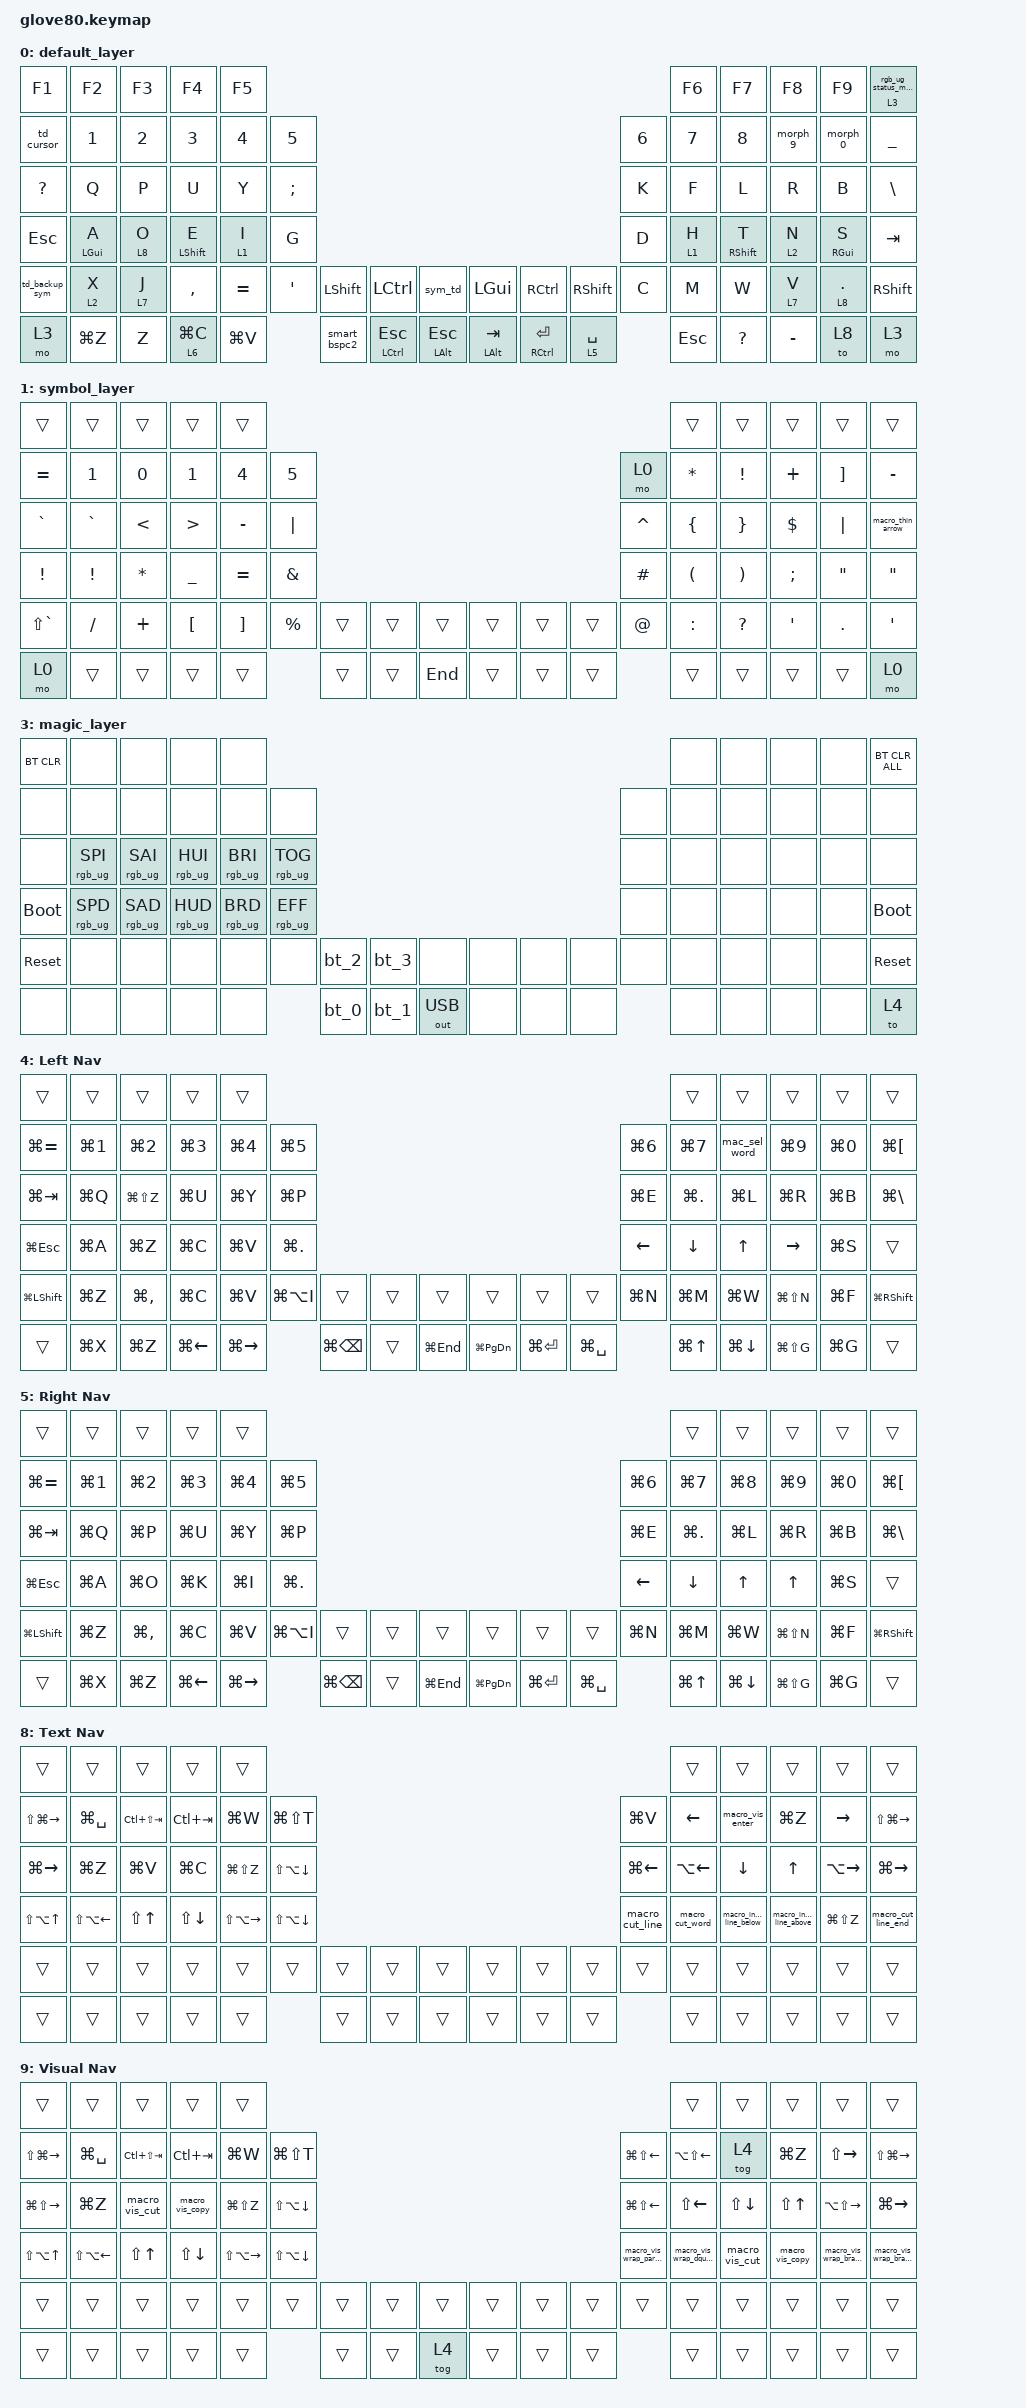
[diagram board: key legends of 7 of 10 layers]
/*
 * Copyright (c) 2020 The ZMK Contributors
 *
 * SPDX-License-Identifier: MIT
 */

#include <dt-bindings/zmk/mouse.h>
#include <behaviors.dtsi>
#include <dt-bindings/zmk/bt.h>
#include <dt-bindings/zmk/keys.h>
#include <dt-bindings/zmk/outputs.h>
#include <dt-bindings/zmk/rgb.h>

// layers

#define DEFAULT 0
#define LOWER 1
#define MAGIC 2
#define FACTORY_TEST 3
#define SYMBOL 4
#define NAV 5
#define LAUNCHER 6
#define CMD_NUM_LAY_2 7
#define TEXT_NAV 8
#define VISUAL_NAV 9
#define KEYS_L 0 1 2 3 4 10 11 12 13 14 15 22 23 24 25 26 27 34 35 36 37 38 39 46 47 48 49 50 51 52 53 54 69 70 71
#define KEYS_R 5 6 7 8 9 16 17 18 19 20 21 28 29 30 31 32 33 40 41 42 43 44 45 55 56 57 58 59 60 61 62 63 72 73 74

/ {
    behaviors {
        // For the "layer" key, it'd nice to be able to use it as either a shift or a toggle.
        // Configure it as a tap dance, so the first tap (or hold) is a &mo and the second tap is a &to

        layer_td: tap_dance_0 {
            compatible = "zmk,behavior-tap-dance";
            label = "LAYER_TAP_DANCE";
            #binding-cells = <0>;
            tapping-term-ms = <200>;
            bindings = <&mo 2>, <&to 2>;
        };

        // Custom Symbol Toggle

        sym_td: symbol_tap_dance {
            compatible = "zmk,behavior-tap-dance";
            label = "SYMBOL_TAP_DANCE";
            #binding-cells = <0>;
            tapping-term-ms = <175>;
            bindings = <&mo 1>, <&to 1>;
        };

        // Custom Nav Toggle

        nav_td: nav_tap_dance {
            compatible = "zmk,behavior-tap-dance";
            label = "NAV_TAP_DANCE";
            #binding-cells = <0>;
            tapping-term-ms = <175>;
            bindings = <&mo 5>, <&to 5>;
        };

        magic: magic_hold_tap {
            compatible = "zmk,behavior-hold-tap";
            label = "MAGIC_HOLD_TAP";
            #binding-cells = <2>;
            flavor = "tap-preferred";
            tapping-term-ms = <200>;
            bindings = <&mo>, <&rgb_ug_status_macro>;
        };

        // Custom Enter/Nav Layer behavior

        ent_nav: enter_nav_layer {
            compatible = "zmk,behavior-hold-tap";
            label = "ENTER_NAV_LAYER";
            #binding-cells = <2>;
            flavor = "tap-preferred";
            tapping-term-ms = <175>;
            quick-tap-ms = <0>;
            retro-tap;
            bindings = <&mo>, <&kp>;
        };

        // Custom Less Than/Launcher Layer behavior

        less_lnch: less_than_launcher {
            compatible = "zmk,behavior-hold-tap";
            label = "LESS_THAN_LAUNCHER";
            #binding-cells = <2>;
            flavor = "tap-preferred";
            tapping-term-ms = <220>;
            quick-tap-ms = <200>;
            require-prior-idle-ms = <125>;
            retro-tap;
            bindings = <&mo>, <&kp>;
        };

        #include "macros.dtsi"

        /* Enter key: Tap for Enter, Hold for Command/GUI */

        enter_cmd: enter_command {
            compatible = "zmk,behavior-hold-tap";
            label = "ENTER_COMMAND";
            #binding-cells = <2>;
            tapping-term-ms = <200>;
            quick-tap-ms = <175>;
            flavor = "balanced";
            bindings = <&kp>, <&kp>;
        };

        /* Left thumb backspace that becomes Shift when held */

        bs_shift: backspace_shift {
            compatible = "zmk,behavior-hold-tap";
            label = "BACKSPACE_SHIFT";
            #binding-cells = <2>;
            tapping-term-ms = <220>;
            quick-tap-ms = <175>;
            require-prior-idle-ms = <160>;
            flavor = "tap-preferred";
            retro-tap;
            bindings = <&kp>, <&kp>;
        };

        /* Right thumb space that becomes Shift when held */

        sp_shift: space_shift {
            compatible = "zmk,behavior-hold-tap";
            label = "SPACE_SHIFT";
            #binding-cells = <2>;
            tapping-term-ms = <220>;
            quick-tap-ms = <0>;
            require-prior-idle-ms = <140>;
            flavor = "tap-preferred";
            retro-tap;
            bindings = <&kp>, <&kp>;
        };

        sp_nav: space_nav {
            compatible = "zmk,behavior-hold-tap";
            label = "SPACE_NAV";
            #binding-cells = <2>;
            tapping-term-ms = <220>;
            quick-tap-ms = <0>;
            require-prior-idle-ms = <140>;
            flavor = "tap-preferred";
            retro-tap;
            bindings = <&mo>, <&kp>;
        };

        /* Smart Toggle for Sym Layer: Tap=Sticky, DoubleTap=Toggle */
        /* Hold-Tap for Sym Layer: Hold=Momentary(1), Tap=Sticky(1) */
        /* Smart Toggle for Sym Layer: Tap=Sticky(via ht), DoubleTap=Lock(tog) */
        /* Select Word: Normal=right, Shift=left */
        /* Smart Backspace: Normal=BSPC/Shift (Hold-Tap), Shift=DelWord (Option+BSPC) */

        bs_nav: backspace_nav {
            compatible = "zmk,behavior-hold-tap";
            label = "BACKSPACE_NAV";
            #binding-cells = <2>;
            tapping-term-ms = <220>;
            quick-tap-ms = <175>;
            require-prior-idle-ms = <160>;
            flavor = "tap-preferred";
            retro-tap;
            bindings = <&mo>, <&kp>;
        };

        smart_bspc: smart_backspace {
            compatible = "zmk,behavior-mod-morph";
            label = "SMART_BACKSPACE";
            #binding-cells = <0>;
            bindings = <&bs_shift LSHFT BSPC>, <&kp LA(BSPC)>;

            mods = <(MOD_LSFT|MOD_RSFT)>;
        };

        smart_bspc2: smart_backspace_2 {
            compatible = "zmk,behavior-mod-morph";
            label = "SMART_BACKSPACE_2";
            #binding-cells = <0>;
            bindings = <&bs_nav 4 BSPC>, <&kp LA(BSPC)>;

            mods = <(MOD_LSFT|MOD_RSFT)>;
        };

        select_word: select_word {
            compatible = "zmk,behavior-mod-morph";
            label = "SELECT_WORD";
            #binding-cells = <0>;
            bindings = <&Mac_Select_Word_Right>, <&Mac_Select_Word_Left>;

            mods = <(MOD_LSFT|MOD_RSFT)>;
        };

        /* Select Line: Normal=right, Shift=left */

        select_line: select_line {
            compatible = "zmk,behavior-mod-morph";
            label = "SELECT_LINE";
            #binding-cells = <0>;
            bindings = <&Mac_Select_Line_Right>, <&Mac_Select_Line_Left>;

            mods = <(MOD_LSFT|MOD_RSFT)>;
        };

        /* Extend Word: Normal=right, Shift=left */

        extend_word: extend_word {
            compatible = "zmk,behavior-mod-morph";
            label = "EXTEND_WORD";
            #binding-cells = <0>;
            bindings = <&Mac_Extend_Word_Right>, <&Mac_Extend_Word_Left>;

            mods = <(MOD_LSFT|MOD_RSFT)>;
        };

        /* Extend Line: Normal=down, Shift=up */

        extend_line: extend_line {
            compatible = "zmk,behavior-mod-morph";
            label = "EXTEND_LINE";
            #binding-cells = <0>;
            bindings = <&Mac_Extend_Line_Down>, <&Mac_Extend_Line_Up>;

            mods = <(MOD_LSFT|MOD_RSFT)>;
        };

        /* Hold-Tap for Nav Layer: Hold=Momentary(4), Tap=Sticky(4) */
        /* Note: Double-tap to toggle is removed to fix build compatibility constraints */

        lt_nav_enter: layer_tap_nav_enter {
            compatible = "zmk,behavior-hold-tap";
            label = "LAYER_TAP_NAV_ENTER";
            #binding-cells = <2>;
            tapping-term-ms = <175>;
            quick-tap-ms = <0>;
            flavor = "tap-preferred";
            retro-tap;
            bindings = <&mo>, <&kp>;
        };

        lt_launcher: layer_tap_launcher {
            compatible = "zmk,behavior-hold-tap";
            label = "LAYER_TAP_LAUNCHER";
            #binding-cells = <2>;
            tapping-term-ms = <220>;
            quick-tap-ms = <0>;
            require-prior-idle-ms = <180>;
            flavor = "tap-preferred";
            retro-tap;
            bindings = <&mo>, <&kp>;
        };

        mt_ctrl_enter: mod_tap_ctrl_enter {
            compatible = "zmk,behavior-hold-tap";
            label = "MOD_TAP_CTRL_ENTER";
            #binding-cells = <2>;
            tapping-term-ms = <175>;
            quick-tap-ms = <0>;
            flavor = "tap-preferred";
            retro-tap;
            bindings = <&kp>, <&kp>;
        };

        mt_ctrl_esc: mod_tap_ctrl_esc {
            compatible = "zmk,behavior-hold-tap";
            label = "MOD_TAP_CTRL_ESC";
            #binding-cells = <2>;
            tapping-term-ms = <220>;
            quick-tap-ms = <0>;
            require-prior-idle-ms = <140>;
            flavor = "tap-preferred";
            retro-tap;
            bindings = <&kp>, <&kp>;
        };

        mt_opt_esc: mod_tap_opt_esc {
            compatible = "zmk,behavior-hold-tap";
            label = "MOD_TAP_OPT_ESC";
            #binding-cells = <2>;
            tapping-term-ms = <200>;
            quick-tap-ms = <0>;
            require-prior-idle-ms = <140>;
            flavor = "tap-preferred";
            retro-tap;
            bindings = <&kp>, <&kp>;
        };

        mt_opt_tab: mod_tap_opt_tab {
            compatible = "zmk,behavior-hold-tap";
            label = "MOD_TAP_OPT_TAB";
            #binding-cells = <2>;
            tapping-term-ms = <200>;
            quick-tap-ms = <0>;
            require-prior-idle-ms = <140>;
            flavor = "tap-preferred";
            retro-tap;
            bindings = <&kp>, <&kp>;
        };

        hrm_left_index: homerow_mod_left_sym {
            compatible = "zmk,behavior-hold-tap";
            label = "HOMEROW_MOD_LEFT_SYM";
            #binding-cells = <2>;
            tapping-term-ms = <295>;
            quick-tap-ms = <175>;
            require-prior-idle-ms = <200>;
            flavor = "tap-preferred";
            retro-tap;
            bindings = <&mo>, <&kp>;

            hold-trigger-key-positions = <KEYS_R>;
            hold-trigger-on-release;
        };

        hrm_left_ring: homerow_mod_left_ring_sym {
            compatible = "zmk,behavior-hold-tap";
            label = "HOMEROW_MOD_LEFT_RING_SYM";
            #binding-cells = <2>;
            tapping-term-ms = <320>;
            quick-tap-ms = <210>;
            require-prior-idle-ms = <200>;
            flavor = "tap-preferred";
            retro-tap;
            bindings = <&mo>, <&kp>;

            hold-trigger-key-positions = <KEYS_R>;
            hold-trigger-on-release;
        };

        hrm_right_index: homerow_mod_right_sym {
            compatible = "zmk,behavior-hold-tap";
            label = "HOMEROW_MOD_RIGHT_SYM";
            #binding-cells = <2>;
            tapping-term-ms = <270>;
            quick-tap-ms = <160>;
            require-prior-idle-ms = <200>;
            flavor = "tap-preferred";
            retro-tap;
            bindings = <&mo>, <&kp>;

            hold-trigger-key-positions = <KEYS_L>;
            hold-trigger-on-release;
        };

        hrm_right_ring: homerow_mod_right_ring_sym {
            compatible = "zmk,behavior-hold-tap";
            label = "HOMEROW_MOD_RIGHT_RING_SYM";
            #binding-cells = <2>;
            tapping-term-ms = <265>;
            quick-tap-ms = <160>;
            require-prior-idle-ms = <200>;
            flavor = "tap-preferred";
            retro-tap;
            bindings = <&mo>, <&kp>;

            hold-trigger-key-positions = <KEYS_L>;
            hold-trigger-on-release;
        };

        hrm_left_ring_bottom: homerow_mod_left_ring_bottom_layer {
            compatible = "zmk,behavior-hold-tap";
            label = "HOMEROW_MOD_LEFT_RING_BOTTOM_LAYER";
            #binding-cells = <2>;
            tapping-term-ms = <290>;
            quick-tap-ms = <175>;
            require-prior-idle-ms = <200>;
            flavor = "tap-preferred";
            retro-tap;
            bindings = <&mo>, <&kp>;

            hold-trigger-key-positions = <KEYS_R>;
            hold-trigger-on-release;
        };

        hrm_right_ring_bottom: homerow_mod_right_ring_bottom_layer {
            compatible = "zmk,behavior-hold-tap";
            label = "HOMEROW_MOD_RIGHT_RING_BOTTOM_LAYER";
            #binding-cells = <2>;
            tapping-term-ms = <265>;
            quick-tap-ms = <160>;
            require-prior-idle-ms = <200>;
            flavor = "tap-preferred";
            retro-tap;
            bindings = <&mo>, <&kp>;

            hold-trigger-key-positions = <KEYS_L>;
            hold-trigger-on-release;
        };

        hrm_left_middle: homerow_mod_left_shift {
            compatible = "zmk,behavior-hold-tap";
            label = "HOMEROW_MOD_LEFT_SHIFT";
            #binding-cells = <2>;
            tapping-term-ms = <315>;
            quick-tap-ms = <160>;
            require-prior-idle-ms = <200>;
            flavor = "tap-preferred";
            retro-tap;
            bindings = <&kp>, <&kp>;

            hold-trigger-key-positions = <KEYS_R>;
            hold-trigger-on-release;
        };

        hrm_right_middle: homerow_mod_right_shift {
            compatible = "zmk,behavior-hold-tap";
            label = "HOMEROW_MOD_RIGHT_SHIFT";
            #binding-cells = <2>;
            tapping-term-ms = <280>;
            quick-tap-ms = <160>;
            require-prior-idle-ms = <200>;
            flavor = "tap-preferred";
            retro-tap;
            bindings = <&kp>, <&kp>;

            hold-trigger-key-positions = <KEYS_L>;
            hold-trigger-on-release;
        };

        hrm_left_pinky: homerow_mod_left_cmd {
            compatible = "zmk,behavior-hold-tap";
            label = "HOMEROW_MOD_LEFT_CMD";
            #binding-cells = <2>;
            tapping-term-ms = <365>;
            quick-tap-ms = <175>;
            require-prior-idle-ms = <200>;
            flavor = "tap-preferred";
            retro-tap;
            bindings = <&kp>, <&kp>;

            hold-trigger-key-positions = <KEYS_R>;
            hold-trigger-on-release;
        };

        hrm_left_pinky_bottom: homerow_mod_left_pinky_bottom_layer {
            compatible = "zmk,behavior-hold-tap";
            label = "HOMEROW_MOD_LEFT_PINKY_BOTTOM_LAYER";
            #binding-cells = <2>;
            tapping-term-ms = <365>;
            quick-tap-ms = <175>;
            require-prior-idle-ms = <200>;
            flavor = "tap-preferred";
            retro-tap;
            bindings = <&mo>, <&kp>;

            hold-trigger-key-positions = <KEYS_R>;
            hold-trigger-on-release;
        };

        hrm_right_pinky: homerow_mod_right_cmd {
            compatible = "zmk,behavior-hold-tap";
            label = "HOMEROW_MOD_RIGHT_CMD";
            #binding-cells = <2>;
            tapping-term-ms = <300>;
            quick-tap-ms = <160>;
            require-prior-idle-ms = <200>;
            flavor = "tap-preferred";
            retro-tap;
            bindings = <&kp>, <&kp>;

            hold-trigger-key-positions = <KEYS_L>;
            hold-trigger-on-release;
        };

        hrm_right_pinky_bottom: homerow_mod_right_pinky_bottom_layer {
            compatible = "zmk,behavior-hold-tap";
            label = "HOMEROW_MOD_RIGHT_PINKY_BOTTOM_LAYER";
            #binding-cells = <2>;
            tapping-term-ms = <300>;
            quick-tap-ms = <160>;
            require-prior-idle-ms = <200>;
            flavor = "tap-preferred";
            retro-tap;
            bindings = <&mo>, <&kp>;

            hold-trigger-key-positions = <KEYS_L>;
            hold-trigger-on-release;
        };

        /* Smart Toggle for Nav Layer (Layer 4): Tap=Sticky, Hold=Momentary */
        /* Replaced Tap-Dance with Hold-Tap for instant speed (Option A) */
        /* Hold-Tap for Cursor Layer: Hold=Momentary(5), Tap=Sticky(5) */
        /* Smart Toggle for Sym Layer: Tap=Sticky, DoubleTap=Lock(tog) */

        td_backup_sym: tap_dance_backup_sym {
            compatible = "zmk,behavior-tap-dance";
            label = "TAP_DANCE_BACKUP_SYM";
            #binding-cells = <0>;
            tapping-term-ms = <175>;
            bindings = <&sl 6>, <&tog 6>;
        };

        /* Smart Toggle for Cursor Layer: Tap=Sticky, DoubleTap=Lock(tog) */

        td_cursor: tap_dance_cursor {
            compatible = "zmk,behavior-tap-dance";
            label = "TAP_DANCE_CURSOR";
            #binding-cells = <0>;
            tapping-term-ms = <175>;
            bindings = <&sl 0>, <&tog 0>;
        };

        fat_arrow: fat_arrow_morph {
            compatible = "zmk,behavior-mod-morph";
            label = "FAT_ARROW_MORPH";
            #binding-cells = <0>;
            bindings = <&kp MINUS>, <&macro_fat_arrow>;

            mods = <(MOD_LSFT|MOD_RSFT)>;
        };

        add_assign: add_assign_morph {
            compatible = "zmk,behavior-mod-morph";
            label = "ADD_ASSIGN_MORPH";
            #binding-cells = <0>;
            bindings = <&kp PLUS>, <&macro_add_assign>;

            mods = <(MOD_LSFT|MOD_RSFT)>;
        };

        not_equal: not_equal_morph {
            compatible = "zmk,behavior-mod-morph";
            label = "NOT_EQUAL_MORPH";
            #binding-cells = <0>;
            bindings = <&kp COLON>, <&macro_not_equal>;

            mods = <(MOD_LSFT|MOD_RSFT)>;
        };

        underscore_arrow: underscore_arrow_morph {
            compatible = "zmk,behavior-mod-morph";
            label = "UNDERSCORE_ARROW_MORPH";
            #binding-cells = <0>;
            bindings = <&kp UNDER>, <&macro_thin_arrow>;

            mods = <(MOD_LSFT|MOD_RSFT)>;
        };

        morph_9: morph_9_lbracket {
            compatible = "zmk,behavior-mod-morph";
            label = "MORPH_9_LBRACKET";
            #binding-cells = <0>;
            bindings = <&kp N9>, <&macro_lbracket>;

            mods = <(MOD_LSFT|MOD_RSFT)>;
        };

        morph_0: morph_0_rbracket {
            compatible = "zmk,behavior-mod-morph";
            label = "MORPH_0_RBRACKET";
            #binding-cells = <0>;
            bindings = <&kp N0>, <&macro_rbracket>;

            mods = <(MOD_LSFT|MOD_RSFT)>;
        };

        lcurly_sq: lcurly_square {
            compatible = "zmk,behavior-mod-morph";
            label = "LCURLY_SQUARE";
            #binding-cells = <0>;
            bindings = <&kp LBRC>, <&macro_lbracket>;

            mods = <(MOD_LSFT|MOD_RSFT)>;
        };

        rcurly_sq: rcurly_square {
            compatible = "zmk,behavior-mod-morph";
            label = "RCURLY_SQUARE";
            #binding-cells = <0>;
            bindings = <&kp RBRC>, <&macro_rbracket>;

            mods = <(MOD_LSFT|MOD_RSFT)>;
        };
    };

    macros {
        rgb_ug_status_macro: rgb_ug_status_macro_0 {
            label = "RGB_UG_STATUS";
            compatible = "zmk,behavior-macro";
            #binding-cells = <0>;
            bindings = <&rgb_ug RGB_STATUS>;
        };

        bt_0: bt_profile_macro_0 {
            label = "BT_0";
            compatible = "zmk,behavior-macro";
            #binding-cells = <0>;
            bindings = <&out OUT_BLE &bt BT_SEL 0>;
        };

        bt_1: bt_profile_macro_1 {
            label = "BT_1";
            compatible = "zmk,behavior-macro";
            #binding-cells = <0>;
            bindings = <&out OUT_BLE &bt BT_SEL 1>;
        };

        bt_2: bt_profile_macro_2 {
            label = "BT_2";
            compatible = "zmk,behavior-macro";
            #binding-cells = <0>;
            bindings = <&out OUT_BLE &bt BT_SEL 2>;
        };

        bt_3: bt_profile_macro_3 {
            label = "BT_3";
            compatible = "zmk,behavior-macro";
            #binding-cells = <0>;
            bindings = <&out OUT_BLE &bt BT_SEL 3>;
        };
    };

    keymap {
        compatible = "zmk,keymap";

        default_layer {
            bindings = <
&kp F1          &kp F2                      &kp F3                     &kp F4                    &kp F5                                                                                                                                                                                &kp F6                &kp F7                           &kp F8                      &kp F9                         &magic 3 0
&td_cursor      &kp N1                      &kp N2                     &kp N3                    &kp N4               &kp N5                                                                                                                                                   &kp N6  &kp N7                &kp N8                           &morph_9                    &morph_0                       &kp UNDERSCORE
&kp QUESTION    &kp Q                       &kp P                      &kp U                     &kp Y                &kp SEMI                                                                                                                                                 &kp K   &kp F                 &kp L                            &kp R                       &kp B                          &kp BSLH
&kp ESCAPE      &hrm_left_pinky LGUI A      &hrm_left_ring 8 O         &hrm_left_middle LSHFT E  &hrm_left_index 1 I  &kp G                                                                                                                                                    &kp D   &hrm_right_index 1 H  &hrm_right_middle RIGHT_SHIFT T  &hrm_right_ring 2 N         &hrm_right_pinky RGUI S        &kp TAB
&td_backup_sym  &hrm_left_pinky_bottom 2 X  &hrm_left_ring_bottom 7 J  &kp COMMA                 &kp EQUAL            &kp SINGLE_QUOTE  &kp LSHFT     &kp LCTRL                  &sym_td                    &kp LGUI              &kp RCTRL                   &kp RSHFT        &kp C   &kp M                 &kp W                            &hrm_right_ring_bottom 7 V  &hrm_right_pinky_bottom 8 DOT  &kp RSHFT
&mo 3           &kp LG(Z)                   &kp Z                      &lt_launcher 6 LG(C)      &kp LG(V)                              &smart_bspc2  &mt_ctrl_esc LCTRL ESCAPE  &mt_opt_esc LALT ESCAPE    &mt_opt_tab LALT TAB  &mt_ctrl_enter RCTRL ENTER  &sp_nav 5 SPACE          &kp ESCAPE            &kp QUESTION                     &kp MINUS                   &to 8                          &mo 3
            >;
        };

        symbol_layer {
            bindings = <
&trans           &trans           &trans         &trans            &trans                                                                                            &trans                &trans                 &trans         &trans             &trans
&kp EQUAL        &kp N1           &kp NUMBER_0   &kp NUMBER_1      &kp N4             &kp N5                                                            &mo 0        &kp STAR              &kp EXCLAMATION        &kp PLUS       &kp RIGHT_BRACKET  &kp MINUS
&kp GRAVE        &kp GRAVE        &kp LESS_THAN  &kp GREATER_THAN  &kp MINUS          &kp PIPE                                                          &kp CARET    &kp LEFT_BRACE        &kp RIGHT_BRACE        &kp DOLLAR     &kp PIPE           &macro_thin_arrow
&kp EXCLAMATION  &kp EXCLAMATION  &kp ASTERISK   &kp UNDERSCORE    &kp EQUAL          &kp AMPERSAND                                                     &kp HASH     &kp LEFT_PARENTHESIS  &kp RIGHT_PARENTHESIS  &kp SEMICOLON  &kp DOUBLE_QUOTES  &kp DOUBLE_QUOTES
&kp LS(GRAVE)    &kp SLASH        &kp PLUS       &kp LEFT_BRACKET  &kp RIGHT_BRACKET  &kp PERCENT    &trans  &trans  &trans     &trans  &trans  &trans  &kp AT_SIGN  &kp COLON             &kp QUESTION           &kp SQT        &kp DOT            &kp SINGLE_QUOTE
&mo 0            &trans           &trans         &trans            &trans                            &trans  &trans  &kp END    &trans  &trans  &trans               &trans                &trans                 &trans         &trans             &mo 0
            >;
        };

        num_layer {
            display-name = "Num";
            bindings = <
&trans  &trans      &trans        &trans        &trans                                                                                            &trans                 &trans                 &trans                 &trans                 &trans
&trans  &trans      &kp SLASH     &kp ASTERISK  &trans        &trans                                                       &trans                 &trans                 &trans                 &trans                 &trans                 &trans
&trans  &kp COMMA   &kp NUMBER_4  &kp NUMBER_5  &kp NUMBER_6  &kp PLUS                                                     &kp LS(LA(LC(LG(K))))  &kp LC(LEFT)           &kp LC(UP)             &kp LC(RIGHT)          &kp LG(LA(LC(LS(B))))  &trans
&trans  &kp N0      &kp N1        &kp N2        &kp N3        &kp EQUAL                                                    &kp LG(LA(LC(LS(D))))  &kp LG(LA(LC(LS(H))))  &kp LG(LA(LC(LS(T))))  &kp LG(LA(LC(LS(N))))  &kp LG(LA(LC(LS(S))))  &trans
&trans  &kp PERIOD  &kp N7        &kp N8        &kp N9        &kp MINUS  &trans  &trans  &trans    &trans  &trans  &trans  &kp LG(NUMBER_0)       &kp LG(MINUS)          &kp LG(PLUS)           &kp D                  &kp PERIOD             &trans
&trans  &trans      &trans        &trans        &trans                   &trans  &trans  &trans    &trans  &trans  &trans                         &kp LG(SPACE)          &trans                 &trans                 &trans                 &trans
            >;
        };

        magic_layer {
            bindings = <
&bt BT_CLR   &none            &none            &none            &none                                                                                       &none  &none  &none  &none  &bt BT_CLR_ALL
&none        &none            &none            &none            &none            &none                                                               &none  &none  &none  &none  &none  &none
&none        &rgb_ug RGB_SPI  &rgb_ug RGB_SAI  &rgb_ug RGB_HUI  &rgb_ug RGB_BRI  &rgb_ug RGB_TOG                                                     &none  &none  &none  &none  &none  &none
&bootloader  &rgb_ug RGB_SPD  &rgb_ug RGB_SAD  &rgb_ug RGB_HUD  &rgb_ug RGB_BRD  &rgb_ug RGB_EFF                                                     &none  &none  &none  &none  &none  &bootloader
&sys_reset   &none            &none            &none            &none            &none            &bt_2  &bt_3  &none           &none  &none  &none  &none  &none  &none  &none  &none  &sys_reset
&none        &none            &none            &none            &none                             &bt_0  &bt_1  &out OUT_USB    &none  &none  &none         &none  &none  &none  &none  &to 4
            >;
        };

        cmd_arw_nav_left_hand {
            display-name = "Left Nav";
            bindings = <
&trans         &trans      &trans         &trans        &trans                                                                                                                          &trans          &trans         &trans           &trans      &trans
&kp LG(EQUAL)  &kp LG(N1)  &kp LG(N2)     &kp LG(N3)    &kp LG(N4)     &kp LG(N5)                                                                                       &kp LG(N6)      &kp LG(N7)      &mac_sel_word  &kp LG(N9)       &kp LG(N0)  &kp LG(LBKT)
&kp LG(TAB)    &kp LG(Q)   &kp LG(LS(Z))  &kp LG(U)     &kp LG(Y)      &kp LG(P)                                                                                        &kp LG(E)       &kp LG(DOT)     &kp LG(L)      &kp LG(R)        &kp LG(B)   &kp LG(BSLH)
&kp LG(ESC)    &kp LG(A)   &kp LG(Z)      &kp LG(C)     &kp LG(V)      &kp LG(DOT)                                                                                      &kp LEFT_ARROW  &kp DOWN_ARROW  &kp UP_ARROW   &kp RIGHT_ARROW  &kp LG(S)   &trans
&kp LG(LSHFT)  &kp LG(Z)   &kp LG(COMMA)  &kp LG(C)     &kp LG(V)      &kp LG(LA(I))  &trans        &trans  &trans         &trans         &trans         &trans         &kp LG(N)       &kp LG(M)       &kp LG(W)      &kp LG(LS(N))    &kp LG(F)   &kp LG(RSHFT)
&trans         &kp LG(X)   &kp LG(Z)      &kp LG(LEFT)  &kp LG(RIGHT)                 &kp LG(BSPC)  &trans  &kp LG(END)    &kp LG(PG_DN)  &kp LG(ENTER)  &kp LG(SPACE)                  &kp LG(UP)      &kp LG(DOWN)   &kp LG(LS(G))    &kp LG(G)   &trans
            >;
        };

        cmd_arw_nav_right_hand {
            display-name = "Right Nav";
            bindings = <
&trans         &trans      &trans         &trans        &trans                                                                                                                      &trans          &trans        &trans         &trans      &trans
&kp LG(EQUAL)  &kp LG(N1)  &kp LG(N2)     &kp LG(N3)    &kp LG(N4)     &kp LG(N5)                                                                                       &kp LG(N6)  &kp LG(N7)      &kp LG(N8)    &kp LG(N9)     &kp LG(N0)  &kp LG(LBKT)
&kp LG(TAB)    &kp LG(Q)   &kp LG(P)      &kp LG(U)     &kp LG(Y)      &kp LG(P)                                                                                        &kp LG(E)   &kp LG(PERIOD)  &kp LG(L)     &kp LG(R)      &kp LG(B)   &kp LG(BSLH)
&kp LG(ESC)    &kp LG(A)   &kp LG(O)      &kp LG(K)     &kp LG(I)      &kp LG(DOT)                                                                                      &kp LEFT    &kp DOWN_ARROW  &kp UP_ARROW  &kp UP_ARROW   &kp LG(S)   &trans
&kp LG(LSHFT)  &kp LG(Z)   &kp LG(COMMA)  &kp LG(C)     &kp LG(V)      &kp LG(LA(I))  &trans        &trans  &trans         &trans         &trans         &trans         &kp LG(N)   &kp LG(M)       &kp LG(W)     &kp LG(LS(N))  &kp LG(F)   &kp LG(RSHFT)
&trans         &kp LG(X)   &kp LG(Z)      &kp LG(LEFT)  &kp LG(RIGHT)                 &kp LG(BSPC)  &trans  &kp LG(END)    &kp LG(PG_DN)  &kp LG(ENTER)  &kp LG(SPACE)              &kp LG(UP)      &kp LG(DOWN)  &kp LG(LS(G))  &kp LG(G)   &trans
            >;
        };

        launcher_layer {
            display-name = "Launcher";
            bindings = <
&trans  &trans                 &trans                 &trans        &trans                                                                                                                 &trans                 &trans                 &trans                 &trans                 &trans
&trans  &kp LG(LA(ESC))        &kp LG(LA(LC(LS(P))))  &kp LC(UP)    &kp LG(LA(LC(LS(Y))))  &trans                                                                   &kp LS(LA(LC(LG(K))))  &kp LC(LEFT)           &kp LC(UP)             &kp LC(RIGHT)          &kp LG(LA(LC(LS(B))))  &trans
&trans  &kp LG(LA(LC(LS(A))))  &kp LG(LA(LC(LS(O))))  &kp LC(LEFT)  &kp LC(RIGHT)          &kp LG(LA(LC(LS(G))))                                                    &kp LG(LA(LC(LS(D))))  &kp LG(LA(LC(LS(H))))  &kp LG(LA(LC(LS(T))))  &kp LG(LA(LC(LS(N))))  &kp LG(LA(LC(LS(S))))  &trans
&trans  &kp LG(LS(Q))          &kp LG(LA(LC(LS(J))))  &trans        &trans                 &trans                                                                   &kp LG(NUMBER_0)       &kp LG(MINUS)          &kp LG(PLUS)           &kp RG(KP_PLUS)        &kp PERIOD             &trans
&trans  &trans                 &trans                 &trans        &trans                 &trans                 &trans  &trans  &trans    &trans  &trans  &trans  &trans                 &trans                 &trans                 &trans                 &trans                 &trans
&trans  &trans                 &trans                 &trans        &trans                                        &trans  &trans  &trans    &trans  &trans  &trans                         &kp LG(SPACE)          &trans                 &trans                 &trans                 &trans
            >;
        };

        cmd_num_lay_2 {
            display-name = "CmdNum2";
            bindings = <
&trans  &trans               &trans      &trans      &trans                                                                                       &trans   &trans   &trans   &trans                &trans
&trans  &kp RS(RA(RC(F3)))   &kp LG(N4)  &kp LG(N5)  &kp LG(N6)  &kp F14                                                    &kp LS(LG(N5))        &kp F1   &kp F2   &kp F5   &kp LG(RS(NUMBER_2))  &trans
&trans  &kp LG(N0)           &kp LG(N1)  &kp LG(N2)  &kp LG(N3)  &kp F15                                                    &kp LS(LG(NUMBER_4))  &kp F10  &kp F11  &kp F12  &kp RS(LG(N0))        &trans
&trans  &kp RS(RA(RC(F23)))  &kp LG(N7)  &kp LG(N8)  &kp LG(N9)  &kp F16                                                    &kp RS(LG(NUMBER_4))  &kp F7   &kp F8   &kp F9   &kp RS(LG(NUMBER_3))  &trans
&trans  &trans               &trans      &trans      &trans      &trans   &trans  &trans  &trans    &trans  &trans  &trans  &trans                &trans   &trans   &trans   &trans                &trans
&trans  &trans               &trans      &trans      &trans               &trans  &trans  &trans    &trans  &trans  &trans                        &kp F7   &kp F8   &kp F9   &trans                &trans
            >;
        };

        text_navigation {
            display-name = "Text Nav";
            bindings = <
&trans             &trans            &trans           &trans        &trans                                                                                                  &trans           &trans                    &trans                    &trans         &trans
&kp LS(LG(RIGHT))  &kp LG(SPACE)     &kp LC(LS(TAB))  &kp LC(TAB)   &kp LG(W)          &kp LG(LS(T))                                                       &kp LG(V)        &kp LEFT         &macro_vis_enter          &kp LG(Z)                 &kp RIGHT      &kp LS(LG(RIGHT))
&kp LG(RIGHT)      &kp LG(Z)         &kp LG(V)        &kp LG(C)     &kp LG(LS(Z))      &kp LS(LA(DOWN))                                                    &kp LG(LEFT)     &kp LA(LEFT)     &kp DOWN                  &kp UP                    &kp LA(RIGHT)  &kp LG(RIGHT)
&kp LS(LA(UP))     &kp LS(LA(LEFT))  &kp LS(UP)       &kp LS(DOWN)  &kp LS(LA(RIGHT))  &kp LS(LA(DOWN))                                                    &macro_cut_line  &macro_cut_word  &macro_insert_line_below  &macro_insert_line_above  &kp LG(LS(Z))  &macro_cut_line_end
&trans             &trans            &trans           &trans        &trans             &trans            &trans  &trans  &trans    &trans  &trans  &trans  &trans           &trans           &trans                    &trans                    &trans         &trans
&trans             &trans            &trans           &trans        &trans                               &trans  &trans  &trans    &trans  &trans  &trans                   &trans           &trans                    &trans                    &trans         &trans
            >;
        };

        visual_navigation {
            display-name = "Visual Nav";
            bindings = <
&trans             &trans            &trans           &trans           &trans                                                                                                         &trans                   &trans          &trans           &trans                    &trans
&kp LS(LG(RIGHT))  &kp LG(SPACE)     &kp LC(LS(TAB))  &kp LC(TAB)      &kp LG(W)          &kp LG(LS(T))                                                       &kp LG(LS(LEFT))        &kp LA(LS(LEFT))         &tog 4          &kp LG(Z)        &kp LS(RIGHT)             &kp LS(LG(RIGHT))
&kp LG(LS(RIGHT))  &kp LG(Z)         &macro_vis_cut   &macro_vis_copy  &kp LG(LS(Z))      &kp LS(LA(DOWN))                                                    &kp LG(LS(LEFT))        &kp LS(LEFT)             &kp LS(DOWN)    &kp LS(UP)       &kp LA(LS(RIGHT))         &kp LG(RIGHT)
&kp LS(LA(UP))     &kp LS(LA(LEFT))  &kp LS(UP)       &kp LS(DOWN)     &kp LS(LA(RIGHT))  &kp LS(LA(DOWN))                                                    &macro_vis_wrap_parens  &macro_vis_wrap_dquotes  &macro_vis_cut  &macro_vis_copy  &macro_vis_wrap_brackets  &macro_vis_wrap_braces
&trans             &trans            &trans           &trans           &trans             &trans            &trans  &trans  &trans    &trans  &trans  &trans  &trans                  &trans                   &trans          &trans           &trans                    &trans
&trans             &trans            &trans           &trans           &trans                               &trans  &trans  &tog 4    &trans  &trans  &trans                          &trans                   &trans          &trans           &trans                    &trans
            >;
        };
    };
};
